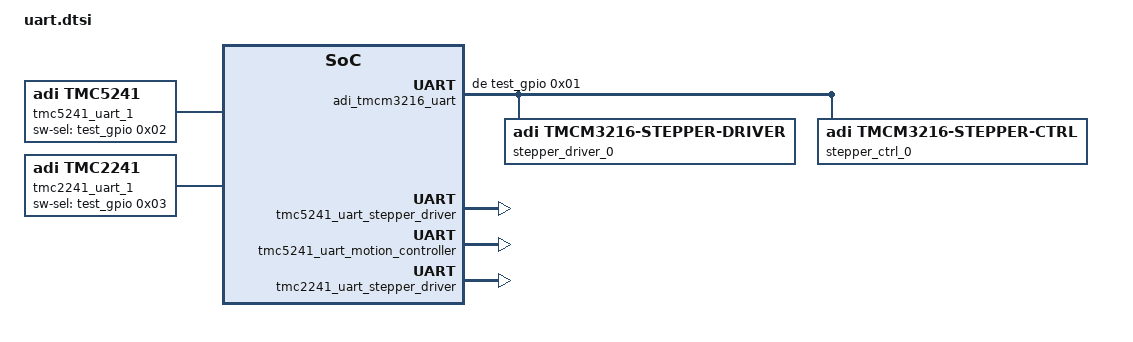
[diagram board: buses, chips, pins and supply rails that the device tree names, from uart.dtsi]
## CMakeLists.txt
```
# SPDX-FileCopyrightText: Copyright (c) 2023 Carl Zeiss Meditec AG
# SPDX-License-Identifier: Apache-2.0

cmake_minimum_required(VERSION 3.28.0)
find_package(Zephyr REQUIRED HINTS $ENV{ZEPHYR_BASE})
project(build_all)

target_sources(app PRIVATE src/main.c)
```

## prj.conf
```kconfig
CONFIG_TEST=y
CONFIG_TEST_USERSPACE=y
CONFIG_LOG=y
CONFIG_STEPPER_LOG_LEVEL_DBG=y
CONFIG_GPIO=y
CONFIG_SPI=y
CONFIG_I2C=y
CONFIG_SERIAL=y
CONFIG_STEPPER=y
CONFIG_EMUL=y
```

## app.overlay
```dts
/*
 * SPDX-FileCopyrightText: Copyright (c) 2024 Carl Zeiss Meditec AG
 * SPDX-License-Identifier: Apache-2.0
 */

/ {
	test {
		#address-cells = <1>;
		#size-cells = <1>;

		test_gpio: gpio@deadbeef {
			compatible = "vnd,gpio";
			reg = <0xdeadbeef 0x1000>;
			gpio-controller;
			#gpio-cells = <0x2>;
			status = "okay";

#include "gpio.dtsi"
		};

		test_spi: spi@33334444 {
			compatible = "zephyr,spi-emul-controller";
			reg = <0x33334444 0x1000>;
			#address-cells = <1>;
			#size-cells = <0>;
			clock-frequency = <2000000>;

			/* one entry for every devices at spi.dtsi */
			cs-gpios = <&test_gpio 0 0>,	/* 0x00 */
				   <&test_gpio 0 0>,	/* 0x01 */
				   <&test_gpio 0 0>,	/* 0x02 */
				   <&test_gpio 0 0>;	/* 0x03 */
			status = "okay";

#include "spi.dtsi"
		};

		test_uart: uart@55556666 {
			compatible = "vnd,serial";
			reg = <0x55556666 0x1000>;
			status = "okay";

#include "uart.dtsi"
		};

		test_i2c: i2c@77778888 {
			compatible = "zephyr,i2c-emul-controller";
			reg = <0x77778888 0x1000>;
			#address-cells = <1>;
			#size-cells = <0>;
			clock-frequency = <100000>;
			status = "okay";

#include "i2c.dtsi"
		};

		zephyr_gpio_step_dir_workq: zephyr-gpio-step-dir {
			compatible = "zephyr,gpio-step-dir-stepper-ctrl";
			step-gpios = <&test_gpio 0 0>;
			dir-gpios = <&test_gpio 0 0>;
			stepper-driver = <&adi_tmc2209>;
		};

		zephyr_gpio_step_dir_counter: zephyr-gpio-step-dir-counter {
			compatible = "zephyr,gpio-step-dir-stepper-ctrl";
			step-gpios = <&test_gpio 0 0>;
			dir-gpios = <&test_gpio 0 0>;
			counter = <&counter0>;
			stepper-driver = <&ti_drv84xx>;
		};

		zephyr_h_bridge_stepper_workq: zephyr-h-bridge-stepper {
			compatible = "zephyr,h-bridge-stepper-ctrl";
			lut-step-gap = <1>;
			gpios = <&test_gpio 0 0>,
				<&test_gpio 0 0>,
				<&test_gpio 0 0>,
				<&test_gpio 0 0>;
			status = "okay";
		};

		zephyr_h_bridge_stepper_counter: zephyr-h-bridge-stepper-counter {
			compatible = "zephyr,h-bridge-stepper-ctrl";
			lut-step-gap = <1>;
			counter = <&counter0>;
			gpios = <&test_gpio 0 0>,
				<&test_gpio 0 0>,
				<&test_gpio 0 0>,
				<&test_gpio 0 0>;
			status = "okay";
		};
	};
};
```

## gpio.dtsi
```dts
/*
 * Copyright (c) 2023 Carl Zeiss Meditec AG
 * SPDX-License-Identifier: Apache-2.0
 */

/****************************************
 *  PLEASE KEEP ALPHABETICALLY SORTED   *
 **************************************
 */

adi_tmc2209: adi-tmc2209 {
	compatible = "adi,tmc2209";
	micro-step-res = <1>;
	m0-gpios = <&test_gpio 0 0>;
	m1-gpios = <&test_gpio 0 0>;
	en-gpios = <&test_gpio 0 0>;
	dual-edge-step;
	status = "okay";
};

allegro_a4979: allegro-a4979 {
	compatible = "allegro,a4979";
	micro-step-res = <1>;
	reset-gpios = <&test_gpio 0 0>;
	en-gpios = <&test_gpio 0 0>;
	m0-gpios = <&test_gpio 0 0>;
	m1-gpios = <&test_gpio 0 0>;
	status = "okay";
};

ti_drv84xx: ti-drv84xx {
	compatible = "ti,drv84xx";
	sleep-gpios = <&test_gpio 0 0>;
	en-gpios = <&test_gpio 0 0>;
	m0-gpios = <&test_gpio 0 0>;
	m1-gpios = <&test_gpio 0 0>;
	status = "okay";
};
```

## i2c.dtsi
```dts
/*
 * SPDX-FileCopyrightText: Copyright The Zephyr Project Contributors
 * SPDX-License-Identifier: Apache-2.0
 */

adi_tmc522x_i2c: adi_tmc522x_i2c@0 {
	compatible = "adi,tmc522x";
	reg = <0x0>;

	clock-frequency = <16000000>;
	chopper-mode = "spreadcycle";
	chm-mode = "spreadcycle";
	status = "okay";

	tmc522x_i2c_stepper_driver: tmc522x_i2c_stepper_driver {
		compatible = "adi,tmc522x-stepper-driver";
		idx = <0>;
		micro-step-res = <16>;
		stallguard2-threshold = <0>;

		ihold = <16>;
		irun = <31>;
		irundelay = <4>;
		iholddelay = <3>;
		tpowerdown = <10>;

		toff = <5>;
		tbl = <3>;
		hstrt = <7>;
		hend = <3>;

		fs-gain = <0>;
		fs-sense = <0>;
		global-scaler = <231>;
	};

	tmc522x_i2c_motion_controller: tmc522x_i2c_motion_controller {
		compatible = "adi,tmc522x-stepper-ctrl";
		idx = <0>;

		vstart = <10>;
		vstop = <10>;
		v1 = <0>;
		amax = <10000>;
		vmax = <10000>;
		dmax = <10000>;
		d1 = <10000>;

		a2 = <10000>;
		v2 = <0>;
		d2 = <10000>;
	};
};
```

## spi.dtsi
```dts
/*
 * SPDX-FileCopyrightText: Copyright (c) 2024 Carl Zeiss Meditec AG
 * SPDX-License-Identifier: Apache-2.0
 */

/*
 ****************************************
 * PLEASE KEEP REG ADDRESSES SEQUENTIAL *
 ****************************************
 */

#include <zephyr/dt-bindings/gpio/gpio.h>

adi_tmc50xx: adi-tmc50xx@0 {
	compatible = "adi,tmc50xx";
	reg = <0x0>;
	spi-max-frequency = <8000000>;
	label = "tmc5041_0";

	poscmp-enable;
	test-mode;
	lock-gconf;
	clock-frequency = <16000000>; /* Internal/External Clock frequency */
	status = "okay";

	tmc50xx_0_stepper_driver: tmc50xx-0-stepper-driver {
		compatible = "adi,tmc50xx-stepper-driver";
		idx = <0>;
		micro-step-res = <256>;
		/* ADI TMC stallguard settings specific to TMC50XX */
		stallguard2-threshold = <30>;
	};

	/* ADI TMC ramp generator as well as current settings */
	tmc50xx_0_motion_controller: tmc50xx-0-motion-controller {
		compatible = "adi,tmc50xx-stepper-ctrl";
		idx = <0>;
		vstart = <1000>;
		vstop = <10>;
		a1 = <10000>;
		v1 = <50000>;
		d1 = <14000>;
		vmax = <900000>;
		amax = <50000>;
		dmax = <7000>;
		tzerowait = <100>;
		vhigh = <900000>;
		vcoolthrs = <900000>;
		ihold = <1>;
		irun = <10>;
		iholddelay = <1>;
	};

	tmc50xx_1_stepper_driver: tmc50xx-1-stepper-driver {
		compatible = "adi,tmc50xx-stepper-driver";
		idx = <1>;
		micro-step-res = <256>;
		/* ADI TMC stallguard settings specific to TMC50XX */
		stallguard2-threshold = <9>;
	};

	tmc50xx_1_motion_controller: tmc50xx-1-motion-controller {
		/* ADI TMC stallguard settings specific to TMC50XX */
		compatible = "adi,tmc50xx-stepper-ctrl";
		idx = <1>;

		/* ADI TMC ramp generator as well as current settings */
		vstart = <10>;
		a1 = <20>;
		v1 = <30>;
		d1 = <40>;
		vmax = <50>;
		amax = <60>;
		dmax = <70>;
		tzerowait = <80>;
		vhigh = <90>;
		vcoolthrs = <100>;
		ihold = <1>;
		irun = <2>;
		iholddelay = <3>;
	};
};

adi_tmc51xx_1: adi-tmc51xx@1 {
	compatible = "adi,tmc51xx";
	reg = <0x01>;
	spi-max-frequency = <8000000>;
	label = "tmc5160_1";

	en-pwm-mode;
	test-mode;
	shaft;
	clock-frequency = <16000000>; /* Internal/External Clock frequency */
	status = "okay";

	tmc51xx_1_stepper_driver: tmc51xx_1_stepper_driver {
		compatible = "adi,tmc51xx-stepper-driver";
		micro-step-res = <256>;
		/* ADI TMC stallguard settings specific to TMC51XX */
		stallguard2-threshold = <9>;
	};

	/* common stepper controller settings */
	tmc51xx_1_motion_controller: tmc51xx_1_motion_controller {
		compatible = "adi,tmc51xx-stepper-ctrl";

		/* ADI TMC ramp generator as well as current settings */
		vstart = <10>;
		a1 = <20>;
		v1 = <30>;
		d1 = <40>;
		vmax = <50>;
		amax = <60>;
		dmax = <70>;
		tzerowait = <80>;
		thigh = <90>;
		tcoolthrs = <100>;
		tpwmthrs = <110>;
		tpowerdown = <120>;
		ihold = <1>;
		irun = <2>;
		iholddelay = <3>;
	};
};

adi_tmc51xx_2: adi-tmc51xx@2 {
	compatible = "adi,tmc51xx";
	reg = <0x02>;
	spi-max-frequency = <8000000>;
	label = "tmc5160_2";

	diag0-gpios = <&test_gpio 0x01 (GPIO_ACTIVE_HIGH | GPIO_PULL_UP)>; /* DIAG pin @0x01 */

	en-pwm-mode;
	test-mode;
	shaft;
	clock-frequency = <16000000>; /* Internal/External Clock frequency */
	status = "okay";

	tmc51xx_2_stepper_driver: tmc51xx-2-stepper-driver {
		compatible = "adi,tmc51xx-stepper-driver";
		micro-step-res = <256>;
		/* ADI TMC stallguard settings specific to TMC51XX */
		stallguard2-threshold = <9>;
	};

	/* common stepper controller settings */
	tmc51xx_2_motion_controller: tmc51xx-2-motion-controller {
		compatible = "adi,tmc51xx-stepper-ctrl";

		/* ADI TMC ramp generator as well as current settings */
		vstart = <10>;
		a1 = <20>;
		v1 = <30>;
		d1 = <40>;
		vmax = <50>;
		amax = <60>;
		dmax = <70>;
		tzerowait = <80>;
		thigh = <90>;
		tcoolthrs = <100>;
		tpwmthrs = <110>;
		tpowerdown = <120>;
		ihold = <1>;
		irun = <2>;
		iholddelay = <3>;
	};
};

adi_tmc522x: adi_tmc522x@3 {
	compatible = "adi,tmc522x";
	reg = <0x03>;
	spi-max-frequency = <4000000>;

	clock-frequency = <16000000>;
	chopper-mode = "spreadcycle";
	chm-mode = "spreadcycle";
	status = "okay";

	tmc522x_stepper_driver: tmc522x_stepper_driver {
		compatible = "adi,tmc522x-stepper-driver";
		idx = <0>;
		micro-step-res = <16>;
		stallguard2-threshold = <0>;

		ihold = <16>;
		irun = <31>;
		irundelay = <4>;
		iholddelay = <3>;
		tpowerdown = <10>;

		toff = <5>;
		tbl = <3>;
		hstrt = <7>;
		hend = <3>;

		fs-gain = <0>;
		fs-sense = <0>;
		global-scaler = <231>;
	};

	tmc522x_motion_controller: tmc522x_motion_controller {
		compatible = "adi,tmc522x-stepper-ctrl";
		idx = <0>;

		vstart = <10>;
		vstop = <10>;
		v1 = <0>;
		amax = <10000>;
		vmax = <10000>;
		dmax = <10000>;
		d1 = <10000>;

		a2 = <10000>;
		v2 = <0>;
		d2 = <10000>;
	};
};
```

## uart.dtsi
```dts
/*
 * SPDX-FileCopyrightText: Copyright (c) 2025 Dipak Shetty
 * SPDX-License-Identifier: Apache-2.0
 */
/****************************************
 * PLEASE KEEP REG ADDRESSES SEQUENTIAL *
 **************************************
 */

#include <zephyr/dt-bindings/gpio/gpio.h>

adi_tmc51xx_uart: adi-tmc51xx {
	compatible = "adi,tmc51xx";

	label = "tmc5160_uart_1";

	en-pwm-mode;
	test-mode; /* ADI TMC Global configuration flags */
	clock-frequency = <16000000>; /* Internal/External Clock frequency */
	status = "okay";

	tmc51xx_stepper_driver: stepper-driver {
		compatible = "adi,tmc51xx-stepper-driver";
		micro-step-res = <256>;
		/* ADI TMC stallguard settings specific to TMC51XX */
		stallguard2-threshold = <9>;
	};

	/* common stepper controller settings */
	tmc51xx_motion_controller: motion-controller {
		compatible = "adi,tmc51xx-stepper-ctrl";

		/* ADI TMC ramp generator as well as current settings */
		vstart = <10>;
		a1 = <20>;
		v1 = <30>;
		d1 = <40>;
		vmax = <50>;
		amax = <60>;
		dmax = <70>;
		tzerowait = <80>;
		thigh = <90>;
		tcoolthrs = <100>;
		tpwmthrs = <110>;
		tpowerdown = <120>;
		ihold = <1>;
		irun = <2>;
		iholddelay = <3>;
	};
};

adi_tmcm3216 {
	#address-cells = <1>;
	#size-cells = <0>;

	adi_tmcm3216_uart: adi-tmcm3216@1 {
		compatible = "adi,tmcm3216";
		reg = <0x1>;
		de-gpios = <&test_gpio 0x01 GPIO_ACTIVE_HIGH>;
		status = "okay";

		stepper_driver_0: stepper-driver {
			compatible = "adi,tmcm3216-stepper-driver";
			idx = <0>;
			micro-step-res = <16>;
			status = "okay";
		};

		stepper_ctrl_0: stepper-ctrl {
			compatible = "adi,tmcm3216-stepper-ctrl";
			idx = <0>;
			status = "okay";
		};
	};
};

adi_tmc5241_uart: adi-tmc5241 {
	compatible = "adi,tmc5241";
	status = "okay";

	label = "tmc5241_uart_1";
	sw-sel-gpios = <&test_gpio 0x02 GPIO_ACTIVE_HIGH>;

	en-pwm-mode;
	shaft; /* ADI TMC Global configuration flags */
	clock-frequency = <16000000>; /* Internal/External Clock frequency */

	tmc5241_uart_stepper_driver: stepper-driver {
		compatible = "adi,tmc5241-stepper-driver";
		micro-step-res = <256>;
		/* ADI TMC stallguard settings specific to TMC5241 */
		stallguard2-threshold = <9>;
	};

	/* ADI TMC ramp generator as well as current settings; TMC5241 only */
	tmc5241_uart_motion_controller: motion-controller {
		compatible = "adi,tmc5241-stepper-ctrl";

		vstart = <10>;
		a1 = <20>;
		v1 = <30>;
		d1 = <40>;
		vmax = <50>;
		amax = <60>;
		dmax = <70>;
		tzerowait = <80>;
		thigh = <90>;
		tcoolthrs = <100>;
		tpwmthrs = <110>;
		tpowerdown = <120>;
		ihold = <1>;
		irun = <2>;
		iholddelay = <3>;
	};
};

adi_tmc2241_uart: adi-tmc2241 {
	compatible = "adi,tmc2241";
	status = "okay";

	label = "tmc2241_uart_1";
	sw-sel-gpios = <&test_gpio 0x03 GPIO_ACTIVE_HIGH>;

	en-pwm-mode;
	shaft;
	clock-frequency = <16000000>; /* Internal/External Clock frequency */

	/* TMC2241 is driver-only; no stepper-ctrl child (no ramp generator hardware) */
	tmc2241_uart_stepper_driver: stepper-driver {
		compatible = "adi,tmc5241-stepper-driver";
		micro-step-res = <256>;
		/* ADI TMC stallguard settings specific to TMC2241 */
		stallguard2-threshold = <9>;
	};
};
```

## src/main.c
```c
/*
 * Copyright (c) 2023 Carl Zeiss Meditec AG
 * SPDX-License-Identifier: Apache-2.0
 */

int main(void)
{
	return 0;
}
```
